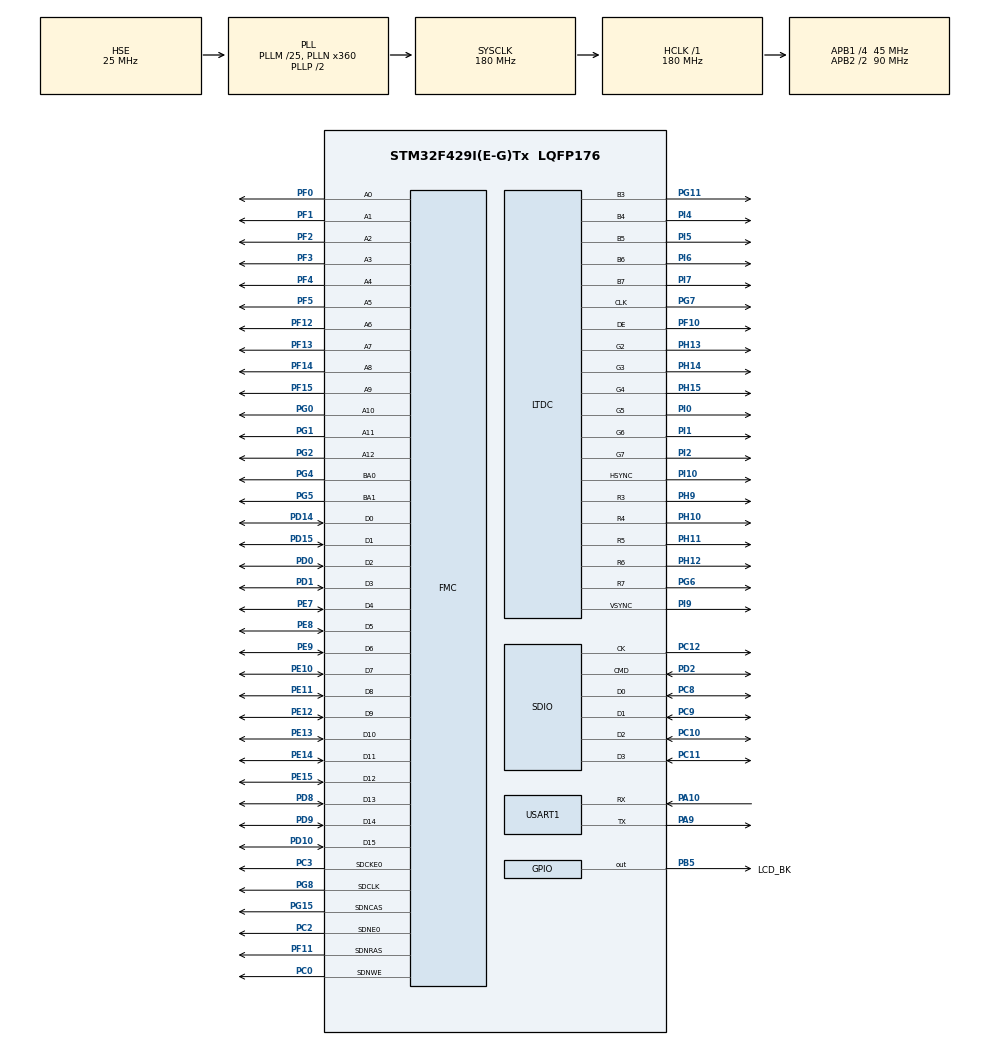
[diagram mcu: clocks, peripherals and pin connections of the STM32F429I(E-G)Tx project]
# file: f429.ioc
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DMA2D.BytesSwap=DMA2D_BYTES_SWAP
DMA2D.ColorMode=DMA2D_OUTPUT_RGB565
DMA2D.LineOffsetMode=DMA2D_LOM_BYTES
Dma.Request0=SDIO_RX
Dma.Request1=SDIO_TX
Dma.SDIO_RX.0.Direction=DMA_PERIPH_TO_MEMORY
Dma.SDIO_RX.0.FIFOMode=DMA_FIFOMODE_ENABLE
Dma.SDIO_RX.0.FIFOThreshold=DMA_FIFO_THRESHOLD_FULL
Dma.SDIO_RX.0.Instance=DMA2_Stream3
Dma.SDIO_RX.0.MemBurst=DMA_MBURST_INC4
Dma.SDIO_RX.0.MemDataAlignment=DMA_MDATAALIGN_WORD
Dma.SDIO_RX.0.MemInc=DMA_MINC_ENABLE
Dma.SDIO_RX.0.Mode=DMA_PFCTRL
Dma.SDIO_RX.0.PeriphBurst=DMA_PBURST_INC4
Dma.SDIO_RX.0.PeriphDataAlignment=DMA_PDATAALIGN_WORD
Dma.SDIO_RX.0.PeriphInc=DMA_PINC_DISABLE
Dma.SDIO_RX.0.Priority=DMA_PRIORITY_LOW
Dma.SDIO_TX.1.Direction=DMA_MEMORY_TO_PERIPH
Dma.SDIO_TX.1.FIFOMode=DMA_FIFOMODE_ENABLE
Dma.SDIO_TX.1.FIFOThreshold=DMA_FIFO_THRESHOLD_FULL
Dma.SDIO_TX.1.Instance=DMA2_Stream6
Dma.SDIO_TX.1.MemBurst=DMA_MBURST_INC4
Dma.SDIO_TX.1.MemDataAlignment=DMA_MDATAALIGN_WORD
Dma.SDIO_TX.1.MemInc=DMA_MINC_ENABLE
Dma.SDIO_TX.1.Mode=DMA_PFCTRL
Dma.SDIO_TX.1.PeriphBurst=DMA_PBURST_INC4
Dma.SDIO_TX.1.PeriphDataAlignment=DMA_PDATAALIGN_WORD
Dma.SDIO_TX.1.PeriphInc=DMA_PINC_DISABLE
Dma.SDIO_TX.1.Priority=DMA_PRIORITY_LOW
FATFS._MAX_SS=4096
FMC.CASLatency1=FMC_SDRAM_CAS_LATENCY_3
FMC.ColumnBitsNumber1=FMC_SDRAM_COLUMN_BITS_NUM_9
FMC.ExitSelfRefreshDelay1=8
FMC.LoadToActiveDelay1=2
FMC.RCDDelay1=2
FMC.RPDelay1=2
FMC.ReadBurst1=FMC_SDRAM_RBURST_ENABLE
FMC.ReadBurst2=FMC_SDRAM_RBURST_ENABLE
FMC.ReadPipeDelay1=FMC_SDRAM_RPIPE_DELAY_1
FMC.RowCycleDelay1=6
FMC.SDClockPeriod1=FMC_SDRAM_CLOCK_PERIOD_2
FMC.SelfRefreshTime1=6
FMC.WriteRecoveryTime1=4
LTDC.ActiveH=PIXELS_H
LTDC.ActiveW=PIXELS_W
LTDC.Alpha0_L1=255
LTDC.Alpha_L0=255
LTDC.Alpha_L1=0
LTDC.BlendingFactor1_L0=LTDC_BLENDING_FACTOR1_PAxCA
LTDC.BlendingFactor2_L0=LTDC_BLENDING_FACTOR2_PAxCA
LTDC.FBStartAdress_L0=LTDC_BUFF_ADDR
LTDC.HBP=140
LTDC.HFP=160
LTDC.HSync=20
LTDC.ImageHeight_L0=PIXELS_H
LTDC.ImageWidth_L0=PIXELS_W
LTDC.Layers=0
LTDC.PixelFormat_L0=LTDC_PIXEL_FORMAT_RGB565
LTDC.VBP=20
LTDC.VFP=12
LTDC.VSync=3
LTDC.WindowX1_L0=PIXELS_W
LTDC.WindowX1_L1=1024
LTDC.WindowY1_L0=PIXELS_H
LTDC.WindowY1_L1=600
Mcu.Family=STM32F4
Mcu.Name=STM32F429I(E-G)Tx
Mcu.Package=LQFP176
Mcu.UserConstants=LTDC_BUFF_ADDR,0XC0000000;PIXELS_W,1024;PIXELS_H,600;PIXELS_DIR,1
NVIC.DMA2D_IRQn=true\:0\:0\:false\:false\:true\:true\:true
NVIC.DMA2_Stream3_IRQn=true\:0\:0\:false\:false\:true\:false\:true
NVIC.DMA2_Stream6_IRQn=true\:0\:0\:false\:false\:true\:false\:true
NVIC.LTDC_IRQn=true\:0\:0\:false\:false\:true\:true\:true
NVIC.PriorityGroup=NVIC_PRIORITYGROUP_4
NVIC.SDIO_IRQn=true\:0\:0\:false\:false\:true\:true\:true
NVIC.TIM6_DAC_IRQn=true\:0\:0\:false\:false\:true\:true\:true
PA10.Mode=Asynchronous
PA10.Signal=USART1_RX
PA13.Mode=Serial_Wire
PA13.Signal=SYS_JTMS-SWDIO
PA14.Mode=Serial_Wire
PA14.Signal=SYS_JTCK-SWCLK
PA9.Mode=Asynchronous
PA9.Signal=USART1_TX
PB5.GPIO_Label=LCD_BK
PB5.Signal=GPIO_Output
PC0.Signal=FMC_SDNWE
PC10.Mode=SD_4_bits_Wide_bus
PC10.Signal=SDIO_D2
PC11.Mode=SD_4_bits_Wide_bus
PC11.Signal=SDIO_D3
PC12.Mode=SD_4_bits_Wide_bus
PC12.Signal=SDIO_CK
PC2.Mode=SdramChipSelect1_1
PC2.Signal=FMC_SDNE0
PC3.Mode=SdramChipSelect1_1
PC3.Signal=FMC_SDCKE0
PC8.Mode=SD_4_bits_Wide_bus
PC8.Signal=SDIO_D0
PC9.Mode=SD_4_bits_Wide_bus
PC9.Signal=SDIO_D1
PD0.Signal=FMC_D2_DA2
PD1.Signal=FMC_D3_DA3
PD10.Signal=FMC_D15_DA15
PD14.Signal=FMC_D0_DA0
PD15.Signal=FMC_D1_DA1
PD2.Mode=SD_4_bits_Wide_bus
PD2.Signal=SDIO_CMD
PD8.Signal=FMC_D13_DA13
PD9.Signal=FMC_D14_DA14
PE0.Signal=FMC_NBL0
PE1.Signal=FMC_NBL1
PE10.Signal=FMC_D7_DA7
PE11.Signal=FMC_D8_DA8
PE12.Signal=FMC_D9_DA9
PE13.Signal=FMC_D10_DA10
PE14.Signal=FMC_D11_DA11
PE15.Signal=FMC_D12_DA12
PE7.Signal=FMC_D4_DA4
PE8.Signal=FMC_D5_DA5
PE9.Signal=FMC_D6_DA6
PF0.Signal=FMC_A0
PF1.Signal=FMC_A1
PF10.GPIO_Speed=GPIO_SPEED_FREQ_VERY_HIGH
PF10.Mode=RGB565
PF10.Signal=LTDC_DE
PF11.Signal=FMC_SDNRAS
PF12.Signal=FMC_A6
PF13.Signal=FMC_A7
PF14.Signal=FMC_A8
PF15.Signal=FMC_A9
PF2.Signal=FMC_A2
PF3.Signal=FMC_A3
PF4.Signal=FMC_A4
PF5.Signal=FMC_A5
PG0.Signal=FMC_A10
PG1.Signal=FMC_A11
PG11.GPIO_Speed=GPIO_SPEED_FREQ_VERY_HIGH
PG11.Mode=RGB565
PG11.Signal=LTDC_B3
PG15.Signal=FMC_SDNCAS
PG2.Signal=FMC_A12
PG4.Signal=FMC_A14_BA0
PG5.Signal=FMC_A15_BA1
PG6.GPIO_Speed=GPIO_SPEED_FREQ_VERY_HIGH
PG6.Mode=RGB565
PG6.Signal=LTDC_R7
PG7.GPIO_Speed=GPIO_SPEED_FREQ_VERY_HIGH
PG7.Mode=RGB565
PG7.Signal=LTDC_CLK
PG8.Signal=FMC_SDCLK
PH0/OSC_IN.Mode=HSE-External-Oscillator
PH0/OSC_IN.Signal=RCC_OSC_IN
PH1/OSC_OUT.Mode=HSE-External-Oscillator
PH1/OSC_OUT.Signal=RCC_OSC_OUT
PH10.GPIO_Speed=GPIO_SPEED_FREQ_VERY_HIGH
PH10.Mode=RGB565
PH10.Signal=LTDC_R4
PH11.GPIO_Speed=GPIO_SPEED_FREQ_VERY_HIGH
PH11.Mode=RGB565
PH11.Signal=LTDC_R5
PH12.GPIO_Speed=GPIO_SPEED_FREQ_VERY_HIGH
PH12.Mode=RGB565
PH12.Signal=LTDC_R6
PH13.GPIO_Speed=GPIO_SPEED_FREQ_VERY_HIGH
PH13.Mode=RGB565
PH13.Signal=LTDC_G2
PH14.GPIO_Speed=GPIO_SPEED_FREQ_VERY_HIGH
PH14.Mode=RGB565
PH14.Signal=LTDC_G3
PH15.GPIO_Speed=GPIO_SPEED_FREQ_VERY_HIGH
PH15.Mode=RGB565
PH15.Signal=LTDC_G4
PH9.GPIO_Speed=GPIO_SPEED_FREQ_VERY_HIGH
PH9.Mode=RGB565
PH9.Signal=LTDC_R3
PI0.GPIO_Speed=GPIO_SPEED_FREQ_VERY_HIGH
PI0.Mode=RGB565
PI0.Signal=LTDC_G5
PI1.GPIO_Speed=GPIO_SPEED_FREQ_VERY_HIGH
PI1.Mode=RGB565
PI1.Signal=LTDC_G6
PI10.GPIO_Speed=GPIO_SPEED_FREQ_VERY_HIGH
PI10.Mode=RGB565
PI10.Signal=LTDC_HSYNC
PI2.GPIO_Speed=GPIO_SPEED_FREQ_VERY_HIGH
PI2.Mode=RGB565
PI2.Signal=LTDC_G7
PI4.GPIO_Speed=GPIO_SPEED_FREQ_VERY_HIGH
PI4.Mode=RGB565
PI4.Signal=LTDC_B4
PI5.GPIO_Speed=GPIO_SPEED_FREQ_VERY_HIGH
PI5.Mode=RGB565
PI5.Signal=LTDC_B5
PI6.GPIO_Speed=GPIO_SPEED_FREQ_VERY_HIGH
PI6.Mode=RGB565
PI6.Signal=LTDC_B6
PI7.GPIO_Speed=GPIO_SPEED_FREQ_VERY_HIGH
PI7.Mode=RGB565
PI7.Signal=LTDC_B7
PI9.GPIO_Speed=GPIO_SPEED_FREQ_VERY_HIGH
PI9.Mode=RGB565
PI9.Signal=LTDC_VSYNC
ProjectManager.HeapSize=0x1000
ProjectManager.StackSize=0x1000
ProjectManager.TargetToolchain=MDK-ARM V5.27
RCC.48MHZClocksFreq_Value=45000000
RCC.AHBFreq_Value=180000000
RCC.APB1CLKDivider=RCC_HCLK_DIV4
RCC.APB1Freq_Value=45000000
RCC.APB1TimFreq_Value=90000000
RCC.APB2CLKDivider=RCC_HCLK_DIV2
RCC.APB2Freq_Value=90000000
RCC.APB2TimFreq_Value=180000000
RCC.CortexFreq_Value=180000000
RCC.HCLKFreq_Value=180000000
RCC.HSE_VALUE=25000000
RCC.HSI_VALUE=16000000
RCC.LSE_VALUE=32768
RCC.PLLM=25
RCC.PLLN=360
RCC.PLLQ=8
RCC.PLLSAIN=180
RCC.PLLSourceVirtual=RCC_PLLSOURCE_HSE
RCC.SYSCLKFreq_VALUE=180000000
RCC.SYSCLKSource=RCC_SYSCLKSOURCE_PLLCLK
RCC.VCOOutputFreq_Value=360000000
SDIO.ClockDiv=2
SH.FMC_A0.0=FMC_A0,13b-sda1
SH.FMC_A1.0=FMC_A1,13b-sda1
SH.FMC_A10.0=FMC_A10,13b-sda1
SH.FMC_A11.0=FMC_A11,13b-sda1
SH.FMC_A12.0=FMC_A12,13b-sda1
SH.FMC_A14_BA0.0=FMC_BA0,FourSdramBanks1
SH.FMC_A15_BA1.0=FMC_BA1,FourSdramBanks1
SH.FMC_A2.0=FMC_A2,13b-sda1
SH.FMC_A3.0=FMC_A3,13b-sda1
SH.FMC_A4.0=FMC_A4,13b-sda1
SH.FMC_A5.0=FMC_A5,13b-sda1
SH.FMC_A6.0=FMC_A6,13b-sda1
SH.FMC_A7.0=FMC_A7,13b-sda1
SH.FMC_A8.0=FMC_A8,13b-sda1
SH.FMC_A9.0=FMC_A9,13b-sda1
SH.FMC_D0_DA0.0=FMC_D0,sd-16b-d1
SH.FMC_D10_DA10.0=FMC_D10,sd-16b-d1
SH.FMC_D11_DA11.0=FMC_D11,sd-16b-d1
SH.FMC_D12_DA12.0=FMC_D12,sd-16b-d1
SH.FMC_D13_DA13.0=FMC_D13,sd-16b-d1
SH.FMC_D14_DA14.0=FMC_D14,sd-16b-d1
SH.FMC_D15_DA15.0=FMC_D15,sd-16b-d1
SH.FMC_D1_DA1.0=FMC_D1,sd-16b-d1
SH.FMC_D2_DA2.0=FMC_D2,sd-16b-d1
SH.FMC_D3_DA3.0=FMC_D3,sd-16b-d1
SH.FMC_D4_DA4.0=FMC_D4,sd-16b-d1
SH.FMC_D5_DA5.0=FMC_D5,sd-16b-d1
SH.FMC_D6_DA6.0=FMC_D6,sd-16b-d1
SH.FMC_D7_DA7.0=FMC_D7,sd-16b-d1
SH.FMC_D8_DA8.0=FMC_D8,sd-16b-d1
SH.FMC_D9_DA9.0=FMC_D9,sd-16b-d1
SH.FMC_NBL0.0=FMC_NBL0
SH.FMC_NBL1.0=FMC_NBL1
SH.FMC_SDCLK.0=FMC_SDCLK,13b-sda1
SH.FMC_SDNCAS.0=FMC_SDNCAS,13b-sda1
SH.FMC_SDNRAS.0=FMC_SDNRAS,13b-sda1
SH.FMC_SDNWE.0=FMC_SDNWE,13b-sda1
TIM6.AutoReloadPreload=TIM_AUTORELOAD_PRELOAD_ENABLE
TIM6.Period=1000
TIM6.Prescaler=179
USART1.VirtualMode=VM_ASYNC
VP_DMA2D_VS_DMA2D.Mode=DMA2D_Activate
VP_FATFS_VS_SDIO.Mode=SDIO
VP_TIM6_VS_ClockSourceINT.Mode=Enable_Timer
board=custom

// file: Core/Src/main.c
/* USER CODE BEGIN Header */
/**
  ******************************************************************************
  * @file           : main.c
  * @brief          : Main program body
  ******************************************************************************
  * @attention
  *
  * <h2><center>&copy; Copyright (c) 2020 STMicroelectronics.
  * All rights reserved.</center></h2>
  *
  * This software component is licensed by ST under BSD 3-Clause license,
  * the "License"; You may not use this file except in compliance with the
  * License. You may obtain a copy of the License at:
  *                        opensource.org/licenses/BSD-3-Clause
  *
  ******************************************************************************
  */
/* USER CODE END Header */
#include "main.h"
#include "dma.h"
#include "dma2d.h"
#include "fatfs.h"
#include "ltdc.h"
#include "sdio.h"
#include "tim.h"
#include "usart.h"
#include "gpio.h"
#include "fmc.h"

void SystemClock_Config(void);

/* USER CODE BEGIN 0 */

void fsmc_sdram_test(uint16_t x,uint16_t y)
{
	uint32_t i=0;
	uint32_t temp=0;
	uint32_t sval=0;	//在地址0读到的数据
	//每隔16K字节,写入一个数据,总共写入2048个数据,刚好是32M字节
	printf("SDRAM begin\r\n");
	for(i=0;i<32*1024*1024;i+=16*1024)
	{
		*(__IO uint32_t*)(Bank5_SDRAM_ADDR+i)=temp;
		temp++;
	}
	//依次读出之前写入的数据,进行校验
 	for(i=0;i<32*1024*1024;i+=16*1024)
	{
  		temp=*(__IO uint32_t*)(Bank5_SDRAM_ADDR+i);
		if(i==0)sval=temp;
 		else if(temp<=sval)break;//后面读出的数据一定要比第一次读到的数据大.
		printf("SDRAM Capacity:%dKB\r\n",(uint16_t)(temp-sval+1)*16);//打印SDRAM容量
 	}
}

FATFS fs;                 // Work area (file system object) for logical drive
FIL fil;                  // file objects

char filename[] = "0:test.txt";
uint8_t write_dat[] = "Hello,FATFS!\n";
uint16_t write_num = 0;

FRESULT fr;
FIL     fd;

void sd_fatfs_test(void)
{
	printf("\r\n ****** FatFs Example ******\r\n\r\n");

    /*##-1- Register the file system object to the FatFs module ##############*/
		retSD = f_mount(&fs, "0:/", 0);
    if(retSD)
    {
        printf(" mount error : %d \r\n",retSD);
        Error_Handler();
    }
    else
        printf(" mount sucess!!! \r\n");

		fr = f_open(&fd, filename, FA_CREATE_ALWAYS | FA_WRITE);
    if(fr == FR_OK)
    {
        printf("open file \"%s\" ok! \r\n", filename);
    }
    else
    {
        printf("open file \"%s\" error : %d\r\n", filename, fr);
    }

    fr = f_write(&fd, write_dat, sizeof(write_dat), (void *)&write_num);
    if(fr == FR_OK)
    {
        printf("write %d dat to file \"%s\" ok,dat is \"%s\".\r\n", write_num, filename, write_dat);
    }
    else
    {
        printf("write dat to file \"%s\" error,error code is:%d\r\n", filename, fr);
    }

    fr = f_close(&fd);
    if(fr == FR_OK)
    {
        printf("close file \"%s\" ok!\r\n", filename);
    }
    else
    {
        printf("close file \"%s\" error, error code is:%d.\r\n", filename, fr);
    }

}

#include "lvgl/lvgl.h"
#include "touch.h"

void delay_us(uint32_t nus)
{
	for (int i = 0; i < 40*nus; i++);
}

/* USER CODE END 0 */

int main(void)
{

  /* MCU Configuration--------------------------------------------------------*/

  /* Reset of all peripherals, Initializes the Flash interface and the Systick. */
  HAL_Init();

  /* Configure the system clock */
  SystemClock_Config();

  /* USER CODE BEGIN SysInit */
	//Stm32_Clock_Init(360,25,2,8);   //设置时钟,180Mhz
  /* USER CODE END SysInit */

  /* Initialize all configured peripherals */
  MX_GPIO_Init();
  MX_DMA_Init();
  MX_LTDC_Init();
  MX_FMC_Init();
  MX_USART1_UART_Init();
  MX_SDIO_SD_Init();
  MX_FATFS_Init();
  MX_TIM6_Init();
  //MX_DMA2D_Init();
  /* USER CODE BEGIN 2 */
	MX_SDRAM_InitEx();

	HAL_TIM_Base_Start_IT(&htim6);

	LTDC_Init();

  touch_init();

	lv_init();
	lv_port_disp_init();
	lv_port_indev_init();

	//lv_demo_widgets();
	lv_demo_benchmark();
	//lv_demo_stress();
	//sd_fatfs_test();
	//	HAL_Delay(1000);
		while(1){

			lv_task_handler();
		}
	// LTDC_Fill(20,20,100,100,BLACK);
	//fsmc_sdram_test(30,170);//测试SRAM容量

  /* USER CODE END 2 */

  /* Infinite loop */
  while (1)
  {

  }
}

void SystemClock_Config(void)
{
  RCC_OscInitTypeDef RCC_OscInitStruct = {0};
  RCC_ClkInitTypeDef RCC_ClkInitStruct = {0};
  RCC_PeriphCLKInitTypeDef PeriphClkInitStruct = {0};

  /** Configure the main internal regulator output voltage
  */
  __HAL_RCC_PWR_CLK_ENABLE();
  __HAL_PWR_VOLTAGESCALING_CONFIG(PWR_REGULATOR_VOLTAGE_SCALE1);
  /** Initializes the RCC Oscillators according to the specified parameters
  * in the RCC_OscInitTypeDef structure.
  */
  RCC_OscInitStruct.OscillatorType = RCC_OSCILLATORTYPE_HSE;
  RCC_OscInitStruct.HSEState = RCC_HSE_ON;
  RCC_OscInitStruct.PLL.PLLState = RCC_PLL_ON;
  RCC_OscInitStruct.PLL.PLLSource = RCC_PLLSOURCE_HSE;
  RCC_OscInitStruct.PLL.PLLM = 25;
  RCC_OscInitStruct.PLL.PLLN = 360;
  RCC_OscInitStruct.PLL.PLLP = RCC_PLLP_DIV2;
  RCC_OscInitStruct.PLL.PLLQ = 8;
  if (HAL_RCC_OscConfig(&RCC_OscInitStruct) != HAL_OK)
  {
    Error_Handler();
  }
  /** Activate the Over-Drive mode
  */
  if (HAL_PWREx_EnableOverDrive() != HAL_OK)
  {
    Error_Handler();
  }
  /** Initializes the CPU, AHB and APB buses clocks
  */
  RCC_ClkInitStruct.ClockType = RCC_CLOCKTYPE_HCLK|RCC_CLOCKTYPE_SYSCLK
                              |RCC_CLOCKTYPE_PCLK1|RCC_CLOCKTYPE_PCLK2;
  RCC_ClkInitStruct.SYSCLKSource = RCC_SYSCLKSOURCE_PLLCLK;
  RCC_ClkInitStruct.AHBCLKDivider = RCC_SYSCLK_DIV1;
  RCC_ClkInitStruct.APB1CLKDivider = RCC_HCLK_DIV4;
  RCC_ClkInitStruct.APB2CLKDivider = RCC_HCLK_DIV2;

  if (HAL_RCC_ClockConfig(&RCC_ClkInitStruct, FLASH_LATENCY_5) != HAL_OK)
  {
    Error_Handler();
  }
  PeriphClkInitStruct.PeriphClockSelection = RCC_PERIPHCLK_LTDC;
  PeriphClkInitStruct.PLLSAI.PLLSAIN = 180;
  PeriphClkInitStruct.PLLSAI.PLLSAIR = 2;
  PeriphClkInitStruct.PLLSAIDivR = RCC_PLLSAIDIVR_2;
  if (HAL_RCCEx_PeriphCLKConfig(&PeriphClkInitStruct) != HAL_OK)
  {
    Error_Handler();
  }
}

void Error_Handler(void)
{
}

/************************ (C) COPYRIGHT STMicroelectronics *****END OF FILE****/
